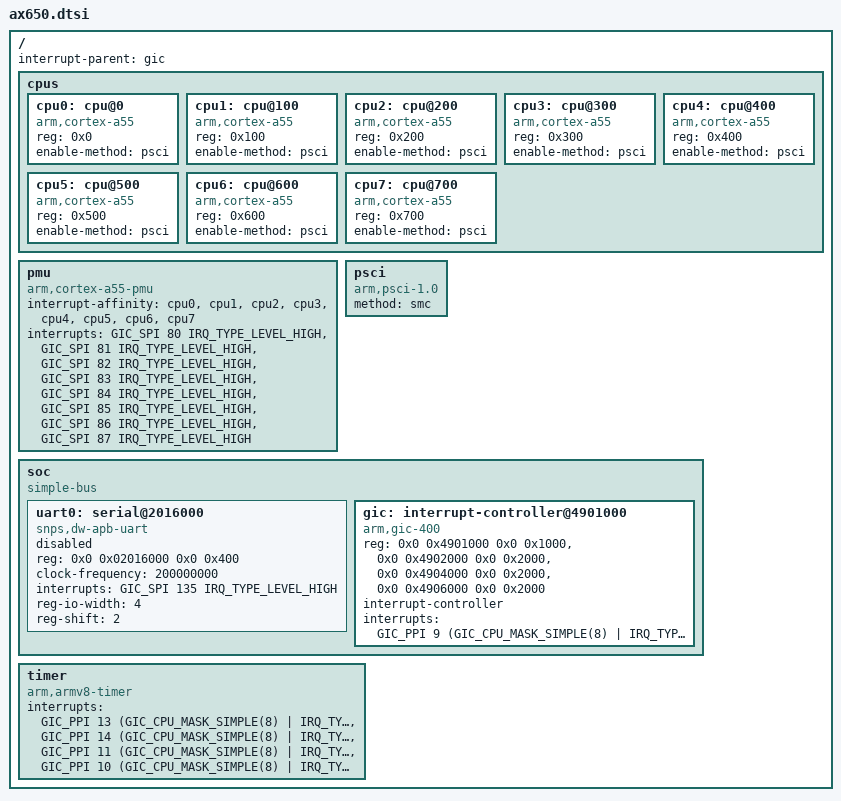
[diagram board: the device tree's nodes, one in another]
// SPDX-License-Identifier: (GPL-2.0+ OR MIT)
/*
 * Copyright 2026 Axera Semiconductor Co., Ltd.
 */

#include <dt-bindings/interrupt-controller/arm-gic.h>

/ {
	#address-cells = <2>;
	interrupt-parent = <&gic>;
	#size-cells = <2>;

	cpus {
		#address-cells = <1>;
		#size-cells = <0>;

		cpu0: cpu@0 {
			compatible = "arm,cortex-a55";
			reg = <0x0>;
			device_type = "cpu";
			enable-method = "psci";
		};

		cpu1: cpu@100 {
			compatible = "arm,cortex-a55";
			reg = <0x100>;
			device_type = "cpu";
			enable-method = "psci";
		};

		cpu2: cpu@200 {
			compatible = "arm,cortex-a55";
			reg = <0x200>;
			device_type = "cpu";
			enable-method = "psci";
		};

		cpu3: cpu@300 {
			compatible = "arm,cortex-a55";
			reg = <0x300>;
			device_type = "cpu";
			enable-method = "psci";
		};

		cpu4: cpu@400 {
			compatible = "arm,cortex-a55";
			reg = <0x400>;
			device_type = "cpu";
			enable-method = "psci";
		};

		cpu5: cpu@500 {
			compatible = "arm,cortex-a55";
			reg = <0x500>;
			device_type = "cpu";
			enable-method = "psci";
		};

		cpu6: cpu@600 {
			compatible = "arm,cortex-a55";
			reg = <0x600>;
			device_type = "cpu";
			enable-method = "psci";
		};

		cpu7: cpu@700 {
			compatible = "arm,cortex-a55";
			reg = <0x700>;
			device_type = "cpu";
			enable-method = "psci";
		};
	};

	pmu {
		compatible = "arm,cortex-a55-pmu";
		interrupt-affinity = <&cpu0>, <&cpu1>, <&cpu2>, <&cpu3>,
				     <&cpu4>, <&cpu5>, <&cpu6>, <&cpu7>;
		interrupts = <GIC_SPI 80 IRQ_TYPE_LEVEL_HIGH>,
			     <GIC_SPI 81 IRQ_TYPE_LEVEL_HIGH>,
			     <GIC_SPI 82 IRQ_TYPE_LEVEL_HIGH>,
			     <GIC_SPI 83 IRQ_TYPE_LEVEL_HIGH>,
			     <GIC_SPI 84 IRQ_TYPE_LEVEL_HIGH>,
			     <GIC_SPI 85 IRQ_TYPE_LEVEL_HIGH>,
			     <GIC_SPI 86 IRQ_TYPE_LEVEL_HIGH>,
			     <GIC_SPI 87 IRQ_TYPE_LEVEL_HIGH>;
	};

	psci {
		compatible = "arm,psci-1.0";
		method = "smc";
	};

	soc {
		compatible = "simple-bus";
		ranges;
		#address-cells = <2>;
		#size-cells = <2>;

		uart0: serial@2016000 {
			compatible = "snps,dw-apb-uart";
			reg = <0x0 0x02016000 0x0 0x400>;
			clock-frequency = <200000000>;
			interrupts = <GIC_SPI 135 IRQ_TYPE_LEVEL_HIGH>;
			reg-io-width = <4>;
			reg-shift = <2>;

			status = "disabled";
		};

		/* GIC-400 register frames start at offset 0x1000. */
		gic: interrupt-controller@4901000 {
			compatible = "arm,gic-400";
			reg = <0x0 0x4901000 0x0 0x1000>,
			      <0x0 0x4902000 0x0 0x2000>,
			      <0x0 0x4904000 0x0 0x2000>,
			      <0x0 0x4906000 0x0 0x2000>;
			#address-cells = <0>;
			#interrupt-cells = <3>;
			interrupt-controller;
			interrupts = <GIC_PPI 9
				     (GIC_CPU_MASK_SIMPLE(8) | IRQ_TYPE_LEVEL_HIGH)>;
		};
	};

	timer {
		compatible = "arm,armv8-timer";
		interrupts = <GIC_PPI 13
			     (GIC_CPU_MASK_SIMPLE(8) | IRQ_TYPE_LEVEL_HIGH)>,
			     <GIC_PPI 14
			     (GIC_CPU_MASK_SIMPLE(8) | IRQ_TYPE_LEVEL_HIGH)>,
			     <GIC_PPI 11
			     (GIC_CPU_MASK_SIMPLE(8) | IRQ_TYPE_LEVEL_HIGH)>,
			     <GIC_PPI 10
			     (GIC_CPU_MASK_SIMPLE(8) | IRQ_TYPE_LEVEL_HIGH)>;
	};
};
